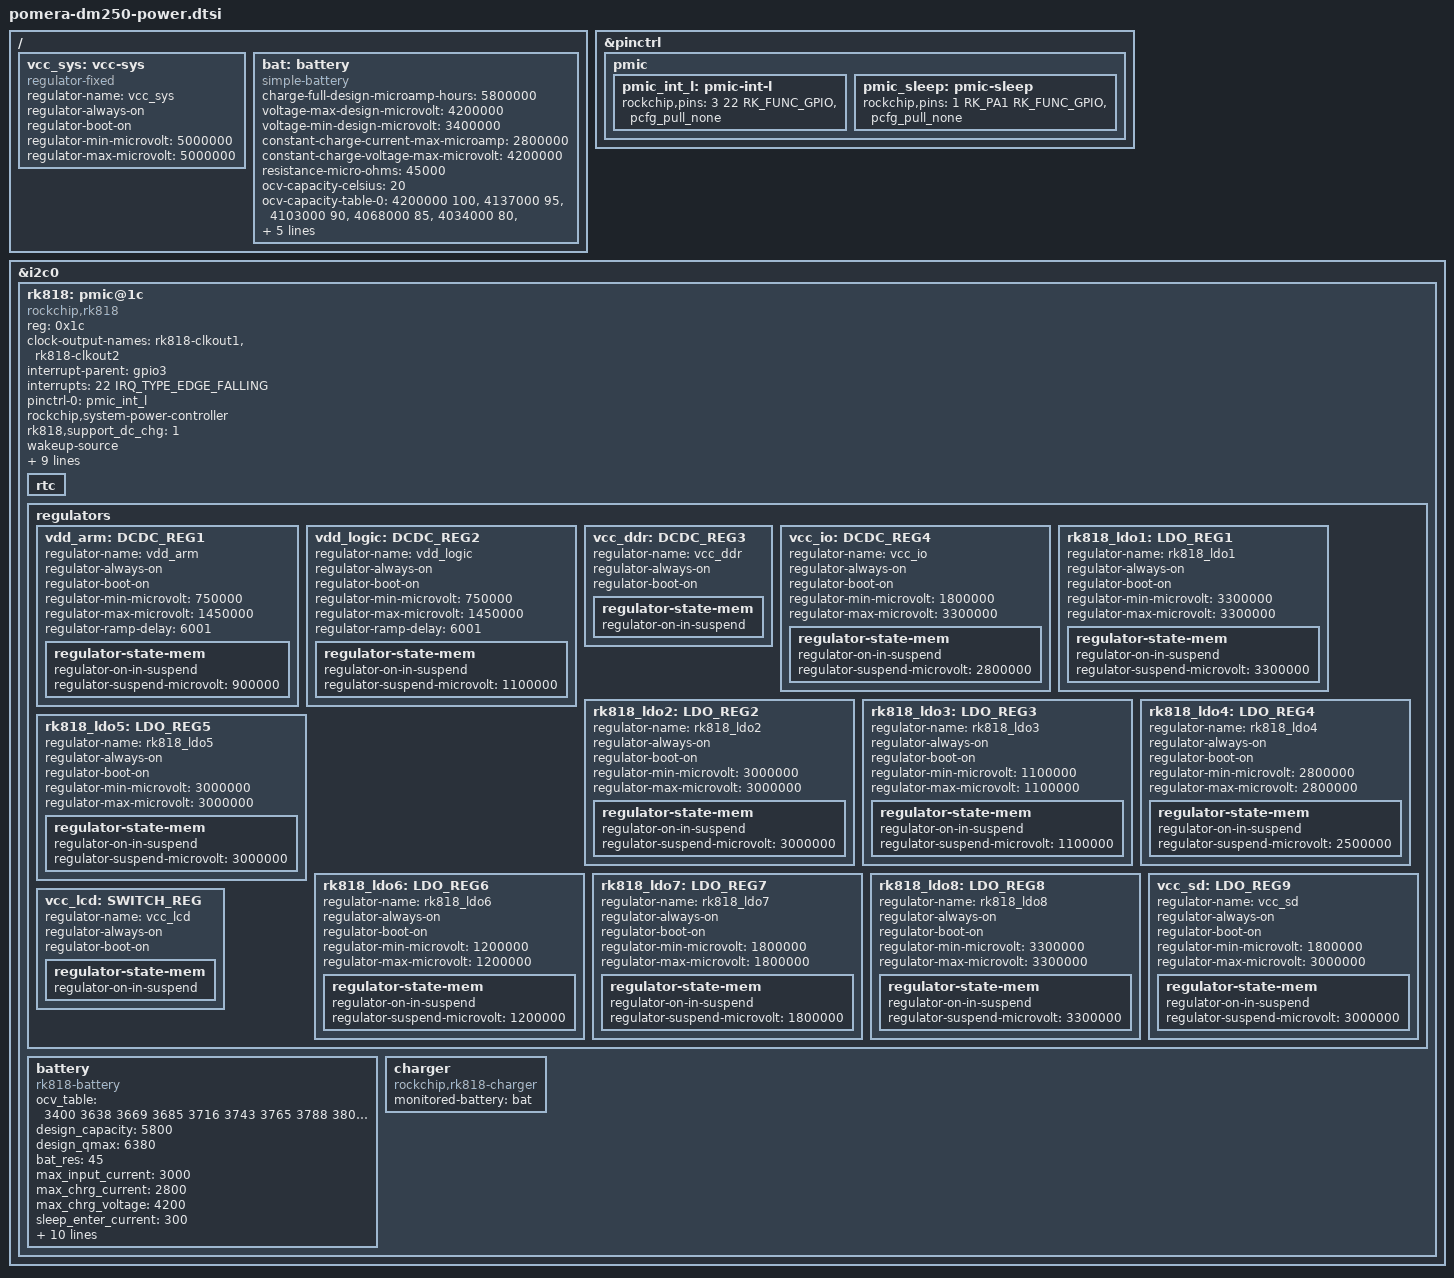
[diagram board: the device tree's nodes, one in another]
// SPDX-License-Identifier: (GPL-2.0+ OR MIT)

&pinctrl {
	pmic {
		pmic_int_l: pmic-int-l {
                        rockchip,pins = <3 22 RK_FUNC_GPIO &pcfg_pull_none>;
			/* rockchip,pins = <1 RK_PB1 RK_FUNC_GPIO &pcfg_pull_none>; */
		};

		/* Pin for switching state between sleep and non-sleep state */
		pmic_sleep: pmic-sleep {
			rockchip,pins = <1 RK_PA1 RK_FUNC_GPIO &pcfg_pull_none>;
		};
        };
};

/ {
	vcc_sys: vcc-sys {
		compatible = "regulator-fixed";
		regulator-name = "vcc_sys";
		regulator-always-on;
		regulator-boot-on;
		regulator-min-microvolt = <5000000>;
		regulator-max-microvolt = <5000000>;
	};

	bat: battery {
		compatible = "simple-battery";

		/* 5800 mAh */
		charge-full-design-microamp-hours = <5800000>;
		/* 4200 mV */
		voltage-max-design-microvolt = <4200000>;
		/* 3400 mV */
		voltage-min-design-microvolt = <3400000>;
		/* 2800 mA */
		constant-charge-current-max-microamp = <2800000>;
		/* 4200 mV */
		constant-charge-voltage-max-microvolt = <4200000>;
		/* 45 mOhm */
		resistance-micro-ohms = <45000>;
		ocv-capacity-celsius = <20>;
		ocv-capacity-table-0 =
			<4200000 100>,
			<4137000 95>,
			<4103000 90>,
			<4068000 85>,
			<4034000 80>,
			<3988000 75>,
			<3937000 70>,
			<3914000 65>,
			<3891000 60>,
			<3869000 55>,
			<3848000 50>,
			<3828000 45>,
			<3808000 40>,
			<3788000 35>,
			<3765000 30>,
			<3743000 25>,
			<3716000 20>,
			<3685000 15>,
			<3669000 10>,
			<3638000 5>,
			<3400000 0>;
	};
};

&i2c0 {
	status = "okay";

	rk818: pmic@1c {
		compatible = "rockchip,rk818";
		status = "okay";
		reg = <0x1c>;
		clock-output-names = "rk818-clkout1", "rk818-clkout2";

		/** from vendor's 3.10 kernel -- conflicts with uart?! **/
		/* interrupt-parent = <&gpio1>; */
		/* interrupts = <9 IRQ_TYPE_EDGE_FALLING>; */

		/** placeholder -- does not seem to be connected to anything  **/
		interrupt-parent = <&gpio3>;
		interrupts = <22 IRQ_TYPE_EDGE_FALLING>;
		
		pinctrl-names = "default";
		pinctrl-0 = <&pmic_int_l>;
		rockchip,system-power-controller;
                rk818,support_dc_chg = <1>; /*1: dc chg; 0:usb chg*/
		wakeup-source;
		#clock-cells = <1>;
		extcon = <&usb2phy>;

		vcc1-supply = <&vcc_sys>;
		vcc2-supply = <&vcc_sys>;
		vcc3-supply = <&vcc_sys>;
		vcc4-supply = <&vcc_sys>;
		vcc6-supply = <&vcc_sys>;
		vcc7-supply = <&vcc_sys>;
		vcc8-supply = <&vcc_sys>;
		vcc9-supply = <&vcc_io>;

		/** does not appear to work with mainline's driver **/
		rtc {
			status = "okay";
		};

		regulators {
			vdd_arm: DCDC_REG1 {
				regulator-name = "vdd_arm";
				regulator-always-on;
				regulator-boot-on;
				regulator-min-microvolt = <750000>;
				regulator-max-microvolt = <1450000>;
				regulator-ramp-delay = <6001>;
				regulator-state-mem {
					regulator-on-in-suspend;
					regulator-suspend-microvolt = <900000>;
				};
			};

			vdd_logic: DCDC_REG2 {
				regulator-name = "vdd_logic";
				regulator-always-on;
				regulator-boot-on;
				regulator-min-microvolt = <750000>;
				regulator-max-microvolt = <1450000>;
				regulator-ramp-delay = <6001>;
				regulator-state-mem {
					regulator-on-in-suspend;
					regulator-suspend-microvolt = <1100000>;
				};
			};

			vcc_ddr: DCDC_REG3 {
				regulator-name = "vcc_ddr";
				regulator-always-on;
				regulator-boot-on;
				regulator-state-mem {
					regulator-on-in-suspend;
				};
			};

			vcc_io: DCDC_REG4 {
				regulator-name = "vcc_io";
				regulator-always-on;
				regulator-boot-on;
				regulator-min-microvolt = <1800000>;
				regulator-max-microvolt = <3300000>;
				regulator-state-mem {
					regulator-on-in-suspend;
					regulator-suspend-microvolt = <2800000>;
				};
			};

			rk818_ldo1: LDO_REG1 {
				regulator-name = "rk818_ldo1";
				regulator-always-on;
				regulator-boot-on;
				regulator-min-microvolt = <3300000>;
				regulator-max-microvolt = <3300000>;
				regulator-state-mem {
					regulator-on-in-suspend;
					regulator-suspend-microvolt = <3300000>;
				};
			};

			rk818_ldo2: LDO_REG2 {
				regulator-name = "rk818_ldo2";
				regulator-always-on;
				regulator-boot-on;
				regulator-min-microvolt = <3000000>;
				regulator-max-microvolt = <3000000>;
				regulator-state-mem {
					regulator-on-in-suspend;
					regulator-suspend-microvolt = <3000000>;
				};
			};

			rk818_ldo3: LDO_REG3 {
				regulator-name = "rk818_ldo3";
				regulator-always-on;
				regulator-boot-on;
				regulator-min-microvolt = <1100000>;
				regulator-max-microvolt = <1100000>;
				regulator-state-mem {
					regulator-on-in-suspend;
					regulator-suspend-microvolt = <1100000>;
				};
			};

			rk818_ldo4: LDO_REG4 {
				regulator-name = "rk818_ldo4";
				regulator-always-on;
				regulator-boot-on;
				regulator-min-microvolt = <2800000>;
				regulator-max-microvolt = <2800000>;
				regulator-state-mem {
					regulator-on-in-suspend;
					regulator-suspend-microvolt = <2500000>;
				};
			};

			rk818_ldo5: LDO_REG5 {
				regulator-name = "rk818_ldo5";
				regulator-always-on;
				regulator-boot-on;
				regulator-min-microvolt = <3000000>;
				regulator-max-microvolt = <3000000>;
				regulator-state-mem {
					regulator-on-in-suspend;
					regulator-suspend-microvolt = <3000000>;
				};
			};

			rk818_ldo6: LDO_REG6 {
				regulator-name = "rk818_ldo6";
				regulator-always-on;
				regulator-boot-on;
				regulator-min-microvolt = <1200000>;
				regulator-max-microvolt = <1200000>;
				regulator-state-mem {
					regulator-on-in-suspend;
					regulator-suspend-microvolt = <1200000>;
				};
			};

			rk818_ldo7: LDO_REG7 {
				regulator-name = "rk818_ldo7";
				regulator-always-on;
				regulator-boot-on;
				regulator-min-microvolt = <1800000>;
				regulator-max-microvolt = <1800000>;
				regulator-state-mem {
					regulator-on-in-suspend;
					regulator-suspend-microvolt = <1800000>;
				};
			};

			rk818_ldo8: LDO_REG8 {
				regulator-name = "rk818_ldo8";
				regulator-always-on;
				regulator-boot-on;
				regulator-min-microvolt = <3300000>;
				regulator-max-microvolt = <3300000>;
				regulator-state-mem {
					regulator-on-in-suspend;
					regulator-suspend-microvolt = <3300000>;
				};
			};

			vcc_sd: LDO_REG9 {
				regulator-name = "vcc_sd";
				regulator-always-on;
				regulator-boot-on;
				regulator-min-microvolt = <1800000>;
				regulator-max-microvolt = <3000000>;
				regulator-state-mem {
					regulator-on-in-suspend;
					regulator-suspend-microvolt = <3000000>;
				};
			};

                        /* lcd ? */
			vcc_lcd: SWITCH_REG {
				regulator-name = "vcc_lcd";
				regulator-always-on;
				regulator-boot-on;
				regulator-state-mem {
					regulator-on-in-suspend;
				};
			};
		};

		/* not yet works */
		battery {
			compatible = "rk818-battery";
                        ocv_table = <3400 3638 3669 3685 3716 3743 3765
				     3788 3808 3828 3848 3869 3891 3914 3937 3988 4034
				     4068 4103 4137 4200>;
		        design_capacity = <5800>;
		        design_qmax = <6380>;
		        bat_res = <45>;
		        max_input_current = <3000>;
		        max_chrg_current = <2800>;
		        max_chrg_voltage = <4200>;
		        sleep_enter_current = <300>;
		        sleep_exit_current = <300>;
		        sleep_filter_current = <100>;
		        power_off_thresd = <3400>;
		        zero_algorithm_vol = <3850>;
		        energy_mode = <0>;
		        fb_temperature = <105>;
		        max_soc_offset = <60>;
		        monitor_sec = <5>;
		        virtual_power = <0>;
		        power_dc2otg = <0>; /* disable 5v out */
		};

		/* not yet works -- not supported in mainline? */
		charger {
			compatible = "rockchip,rk818-charger";
			monitored-battery = <&bat>;
		};
	};
};
